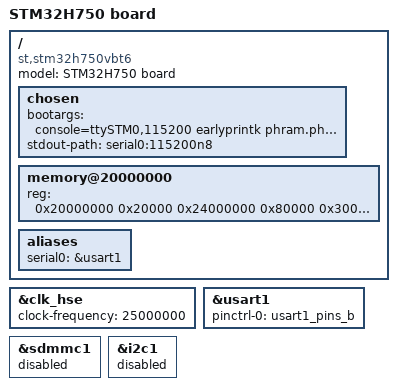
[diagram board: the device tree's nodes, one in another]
/dts-v1/;
#include "stm32h750.dtsi"
#include "stm32h7-pinctrl.dtsi"
#include <dt-bindings/interrupt-controller/irq.h>
#include <dt-bindings/gpio/gpio.h>

/ {
    model = "STM32H750 board";
    compatible = "st,stm32h750vbt6", "st,stm32h750";
    chosen {
        bootargs = "console=ttySTM0,115200 earlyprintk phram.phram=romfs,0x90600000,0x80000 root=mtd:romfs rootfstype=romfs init=/init";
        stdout-path = "serial0:115200n8";
    };

    memory@20000000 {
        device_type = "memory";
        reg = <
        0x20000000 0x20000 
        0x24000000 0x80000
        0x30000000 0x48000
        0x38000000 0x10000
        >;
    };

    // flash@90000000 {
    //     compatible = "physmap-flash";
    //     reg = <0x90000000 0x800000>;
    //     linux,mtd-name = "qspi-rom";
    // };

    aliases {
        serial0 = &usart1;
    };
};

&clk_hse {
    clock-frequency = <25000000>;
};

&usart1 {
    pinctrl-0 = <&usart1_pins_b>;
	pinctrl-names = "default";
	status = "okay";
};

&sdmmc1 { status = "disabled"; };
&i2c1 { status = "disabled"; };
